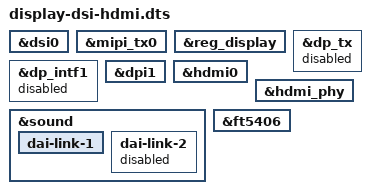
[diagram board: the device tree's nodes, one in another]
/dts-v1/;
/plugin/;

/ {
	fragment@0 {
		target = <&dsi0>;
		__overlay__ {
			status = "okay";
		};
	};

	fragment@1 {
		target = <&mipi_tx0>;
		__overlay__ {
			status = "okay";
		};
	};

	fragment@2 {
		target = <&reg_display>;
		__overlay__ {
			status = "okay";
		};
	};

	fragment@3 {
		target = <&dp_tx>;
		__overlay__ {
			status = "disabled";
		};
	};

	fragment@4 {
		target = <&dp_intf1>;
		__overlay__ {
			status = "disabled";
		};
	};

	fragment@5 {
		target = <&dpi1>;
		__overlay__ {
			status = "okay";
		};
	};

	fragment@6 {
		target = <&hdmi0>;
		__overlay__ {
			status = "okay";
		};
	};

	fragment@7 {
		target = <&hdmi_phy>;
		__overlay__ {
			status = "okay";
		};
	};

	fragment@8 {
		target = <&sound>;
		__overlay__ {
			dai-link-1 { /* HDMI */
				status = "okay";
			};

			dai-link-2 { /* DPTX */
				status = "disabled";
			};
		};
	};
	fragment@9 {
		target = <&ft5406>;
		__overlay__ {
			status = "okay";
		};
	};
};
